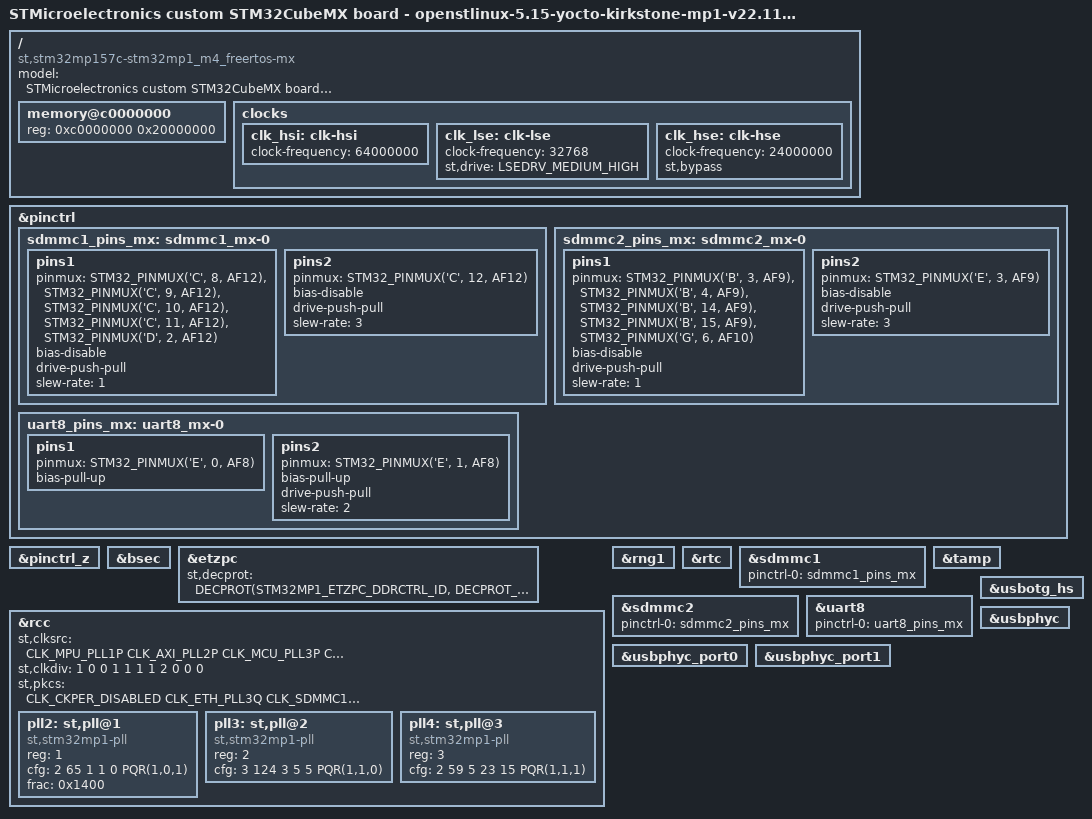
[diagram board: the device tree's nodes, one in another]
/* SPDX-License-Identifier: (GPL-2.0+ OR BSD-3-Clause) */
/*
 * Copyright (C) STMicroelectronics 2023 - All Rights Reserved
 * Author: STM32CubeMX code generation for STMicroelectronics.
 */

/* For more information on Device Tree configuration, please refer to
 * https://wiki.st.com/stm32mpu/wiki/Category:Device_tree_configuration
 */

/dts-v1/;
#include <dt-bindings/pinctrl/stm32-pinfunc.h>
#include <dt-bindings/clock/stm32mp1-clksrc.h>
#include <dt-bindings/soc/st,stm32-etzpc.h>
#include "stm32mp15-mx.dtsi"

#include "stm32mp157.dtsi"
#include "stm32mp15xc.dtsi"
#include "stm32mp15xxac-pinctrl.dtsi"
#include "stm32mp15-ddr.dtsi"

/* USER CODE BEGIN includes */
/* USER CODE END includes */

/ {
	model = "STMicroelectronics custom STM32CubeMX board - openstlinux-5.15-yocto-kirkstone-mp1-v22.11.23";
	compatible = "st,stm32mp157c-stm32mp1_m4_freertos-mx", "st,stm32mp157";

	memory@c0000000 {
		device_type = "memory";
		reg = <0xc0000000 0x20000000>;

		/* USER CODE BEGIN memory */
		/* USER CODE END memory */
	};

	/* USER CODE BEGIN root */
	/* USER CODE END root */

	clocks {
		/* USER CODE BEGIN clocks */
		/* USER CODE END clocks */

		clk_hsi: clk-hsi {
			clock-frequency = <64000000>;

			/* USER CODE BEGIN clk_hsi */
			/* USER CODE END clk_hsi */
		};
		clk_lse: clk-lse {
			clock-frequency = <32768>;
			st,drive = < LSEDRV_MEDIUM_HIGH >;

			/* USER CODE BEGIN clk_lse */
			/* USER CODE END clk_lse */
		};
		clk_hse: clk-hse {
			clock-frequency = <24000000>;
			st,bypass;

			/* USER CODE BEGIN clk_hse */
			/* USER CODE END clk_hse */
		};
	};

}; /*root*/

&pinctrl {
	sdmmc1_pins_mx: sdmmc1_mx-0 {
		pins1 {
			pinmux = <STM32_PINMUX('C', 8, AF12)>, /* SDMMC1_D0 */
					 <STM32_PINMUX('C', 9, AF12)>, /* SDMMC1_D1 */
					 <STM32_PINMUX('C', 10, AF12)>, /* SDMMC1_D2 */
					 <STM32_PINMUX('C', 11, AF12)>, /* SDMMC1_D3 */
					 <STM32_PINMUX('D', 2, AF12)>; /* SDMMC1_CMD */
			bias-disable;
			drive-push-pull;
			slew-rate = <1>;
		};
		pins2 {
			pinmux = <STM32_PINMUX('C', 12, AF12)>; /* SDMMC1_CK */
			bias-disable;
			drive-push-pull;
			slew-rate = <3>;
		};
	};

	sdmmc2_pins_mx: sdmmc2_mx-0 {
		pins1 {
			pinmux = <STM32_PINMUX('B', 3, AF9)>, /* SDMMC2_D2 */
					 <STM32_PINMUX('B', 4, AF9)>, /* SDMMC2_D3 */
					 <STM32_PINMUX('B', 14, AF9)>, /* SDMMC2_D0 */
					 <STM32_PINMUX('B', 15, AF9)>, /* SDMMC2_D1 */
					 <STM32_PINMUX('G', 6, AF10)>; /* SDMMC2_CMD */
			bias-disable;
			drive-push-pull;
			slew-rate = <1>;
		};
		pins2 {
			pinmux = <STM32_PINMUX('E', 3, AF9)>; /* SDMMC2_CK */
			bias-disable;
			drive-push-pull;
			slew-rate = <3>;
		};
	};

	uart8_pins_mx: uart8_mx-0 {
		pins1 {
			pinmux = <STM32_PINMUX('E', 0, AF8)>; /* UART8_RX */
			bias-pull-up;
		};
		pins2 {
			pinmux = <STM32_PINMUX('E', 1, AF8)>; /* UART8_TX */
			bias-pull-up;
			drive-push-pull;
			slew-rate = <2>;
		};
	};

	/* USER CODE BEGIN pinctrl */
	/* USER CODE END pinctrl */
};

&pinctrl_z {
	/* USER CODE BEGIN pinctrl_z */
	/* USER CODE END pinctrl_z */
};

&bsec{
	status = "okay";

	/* USER CODE BEGIN bsec */
	/* USER CODE END bsec */
};

&etzpc{
	status = "okay";
	st,decprot = <
	/*"NS_R S_W" peripherals*/
	DECPROT(STM32MP1_ETZPC_DDRCTRL_ID, DECPROT_NS_R_S_W, DECPROT_LOCK)
	DECPROT(STM32MP1_ETZPC_DDRPHYC_ID, DECPROT_NS_R_S_W, DECPROT_LOCK)
	/*"Non Secured" peripherals*/
	DECPROT(STM32MP1_ETZPC_DMA1_ID, DECPROT_NS_RW, DECPROT_UNLOCK)
	DECPROT(STM32MP1_ETZPC_DMAMUX_ID, DECPROT_NS_RW, DECPROT_UNLOCK)
	DECPROT(STM32MP1_ETZPC_ETH_ID, DECPROT_NS_RW, DECPROT_UNLOCK)
	DECPROT(STM32MP1_ETZPC_RNG1_ID, DECPROT_NS_RW, DECPROT_UNLOCK)
	DECPROT(STM32MP1_ETZPC_UART8_ID, DECPROT_NS_RW, DECPROT_UNLOCK)
	DECPROT(STM32MP1_ETZPC_OTG_ID, DECPROT_NS_RW, DECPROT_UNLOCK)
	/*"Secured" peripherals*/
	DECPROT(STM32MP1_ETZPC_STGENC_ID, DECPROT_S_RW, DECPROT_UNLOCK)
	/*"Mcu Isolation" peripherals*/
	DECPROT(STM32MP1_ETZPC_DMA2_ID, DECPROT_MCU_ISOLATION, DECPROT_UNLOCK)
	DECPROT(STM32MP1_ETZPC_TT_FDCAN_ID, DECPROT_MCU_ISOLATION, DECPROT_UNLOCK)
	DECPROT(STM32MP1_ETZPC_SPI1_ID, DECPROT_MCU_ISOLATION, DECPROT_UNLOCK)
	DECPROT(STM32MP1_ETZPC_TIM12_ID, DECPROT_MCU_ISOLATION, DECPROT_UNLOCK)
	DECPROT(STM32MP1_ETZPC_TIM15_ID, DECPROT_MCU_ISOLATION, DECPROT_UNLOCK)
	DECPROT(STM32MP1_ETZPC_TIM2_ID, DECPROT_MCU_ISOLATION, DECPROT_UNLOCK)
	DECPROT(STM32MP1_ETZPC_TIM4_ID, DECPROT_MCU_ISOLATION, DECPROT_UNLOCK)
	DECPROT(STM32MP1_ETZPC_TIM5_ID, DECPROT_MCU_ISOLATION, DECPROT_UNLOCK)
	DECPROT(STM32MP1_ETZPC_USART2_ID, DECPROT_MCU_ISOLATION, DECPROT_UNLOCK)
	DECPROT(STM32MP1_ETZPC_USART3_ID, DECPROT_MCU_ISOLATION, DECPROT_UNLOCK)
	DECPROT(STM32MP1_ETZPC_USART6_ID, DECPROT_MCU_ISOLATION, DECPROT_UNLOCK)

	/*Restriction: following IDs are not managed  - please to use User-Section if needed:
		  STM32MP1_ETZPC_SRAMx_ID  STM32MP1_ETZPC_RETRAM_ID  STM32MP1_ETZPC_BKPSRAM_ID*/

	/* USER CODE BEGIN etzpc_decprot */
		/*STM32CubeMX generates a basic and standard configuration for ETZPC.
		Additional device configurations can be added here if needed.
		"etzpc" node could be also overloaded in "addons" User-Section.*/
	/* USER CODE END etzpc_decprot */
	>;

	/* USER CODE BEGIN etzpc */
	/* USER CODE END etzpc */
};

&rcc{
	status = "okay";

	/* USER CODE BEGIN rcc */
	/* USER CODE END rcc */

	st,clksrc = <
		CLK_MPU_PLL1P
		CLK_AXI_PLL2P
		CLK_MCU_PLL3P
		CLK_PLL12_HSE
		CLK_PLL3_HSE
		CLK_PLL4_HSE
		CLK_RTC_LSE
		CLK_MCO1_DISABLED
		CLK_MCO2_DISABLED
	>;
	st,clkdiv = <
		1 		/*MPU*/
		0 		/*AXI*/
		0 		/*MCU*/
		1 		/*APB1*/
		1 		/*APB2*/
		1 		/*APB3*/
		1 		/*APB4*/
		2 		/*APB5*/
		0 		/*RTC*/
		0 		/*MCO1*/
		0 		/*MCO2*/
	>;
	st,pkcs = <
		CLK_CKPER_DISABLED
		CLK_ETH_PLL3Q
		CLK_SDMMC12_PLL4P
		CLK_STGEN_HSE
		CLK_USBPHY_PLL4R
		CLK_SPI2S1_PLL4P
		CLK_SPI2S23_DISABLED
		CLK_SPI45_DISABLED
		CLK_SPI6_DISABLED
		CLK_I2C46_DISABLED
		CLK_SDMMC3_DISABLED
		CLK_USBO_PLL4R
		CLK_ADC_DISABLED
		CLK_CEC_DISABLED
		CLK_I2C12_DISABLED
		CLK_I2C35_DISABLED
		CLK_UART1_DISABLED
		CLK_UART24_PLL4Q
		CLK_UART35_PLL4Q
		CLK_UART6_PLL4Q
		CLK_UART78_PLL4Q
		CLK_SPDIF_DISABLED
		CLK_FDCAN_PLL4Q
		CLK_SAI1_DISABLED
		CLK_SAI2_DISABLED
		CLK_SAI3_DISABLED
		CLK_SAI4_DISABLED
		CLK_RNG1_PLL4R
		CLK_LPTIM1_DISABLED
		CLK_LPTIM23_DISABLED
		CLK_LPTIM45_DISABLED
	>;
	pll2:st,pll@1 {
		compatible = "st,stm32mp1-pll";
		reg = <1>;
		cfg = < 2 65 1 1 0 PQR(1,0,1) >;
		frac = < 0x1400 >;
	};
	pll3:st,pll@2 {
		compatible = "st,stm32mp1-pll";
		reg = <2>;
		cfg = < 3 124 3 5 5 PQR(1,1,0) >;
	};
	pll4:st,pll@3 {
		compatible = "st,stm32mp1-pll";
		reg = <3>;
		cfg = < 2 59 5 23 15 PQR(1,1,1) >;
	};
};

&rng1{
	status = "okay";

	/* USER CODE BEGIN rng1 */
	/* USER CODE END rng1 */
};

&rtc{
	status = "okay";

	/* USER CODE BEGIN rtc */
	/* USER CODE END rtc */
};

&sdmmc1{
	pinctrl-names = "default";
	pinctrl-0 = <&sdmmc1_pins_mx>;
	status = "okay";

	/* USER CODE BEGIN sdmmc1 */
	/* USER CODE END sdmmc1 */
};

&sdmmc2{
	pinctrl-names = "default";
	pinctrl-0 = <&sdmmc2_pins_mx>;
	status = "okay";

	/* USER CODE BEGIN sdmmc2 */
	/* USER CODE END sdmmc2 */
};

&tamp{
	status = "okay";

	/* USER CODE BEGIN tamp */
	/* USER CODE END tamp */
};

&uart8{
	pinctrl-names = "default";
	pinctrl-0 = <&uart8_pins_mx>;
	status = "okay";

	/* USER CODE BEGIN uart8 */
	/* USER CODE END uart8 */
};

&usbotg_hs{
	status = "okay";

	/* USER CODE BEGIN usbotg_hs */
	/* USER CODE END usbotg_hs */
};

&usbphyc{
	status = "okay";

	/* USER CODE BEGIN usbphyc */
	/* USER CODE END usbphyc */
};

&usbphyc_port0{
	status = "okay";

	/* USER CODE BEGIN usbphyc_port0 */
	/* USER CODE END usbphyc_port0 */
};

&usbphyc_port1{
	status = "okay";

	/* USER CODE BEGIN usbphyc_port1 */
	/* USER CODE END usbphyc_port1 */
};

/* USER CODE BEGIN addons */
/* USER CODE END addons */

